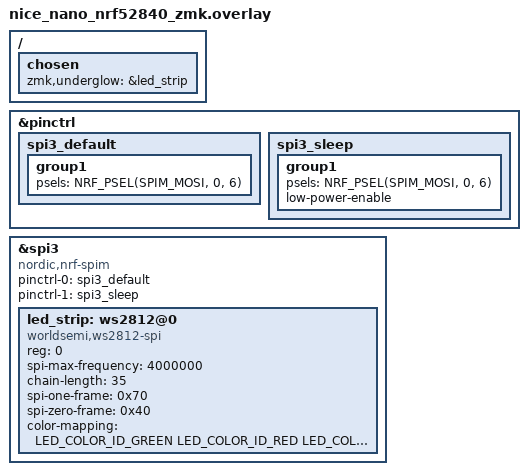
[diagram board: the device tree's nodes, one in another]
/*
 * Copyright (c) 2025 The ZMK Contributors
 * SPDX-License-Identifier: MIT
 * 
 * Aurora Sofle RGB for nice!nano v2
 * OLED is defined in shield-specific overlays
 */

#include <dt-bindings/led/led.h>

// Configure SPI pinctrl for RGB
&pinctrl {
    spi3_default: spi3_default {
        group1 {
            psels = <NRF_PSEL(SPIM_MOSI, 0, 6)>;
        };
    };

    spi3_sleep: spi3_sleep {
        group1 {
            psels = <NRF_PSEL(SPIM_MOSI, 0, 6)>;
            low-power-enable;
        };
    };
};

// Enable SPI for RGB LEDs
&spi3 {
    compatible = "nordic,nrf-spim";
    status = "okay";

    pinctrl-0 = <&spi3_default>;
    pinctrl-1 = <&spi3_sleep>;
    pinctrl-names = "default", "sleep";

    led_strip: ws2812@0 {
        compatible = "worldsemi,ws2812-spi";
        reg = <0>;
        spi-max-frequency = <4000000>;
        
        // Aurora Sofle: 35 LEDs per side (29 per-key + 6 underglow)
        chain-length = <35>;
        
        spi-one-frame = <0x70>;
        spi-zero-frame = <0x40>;
        color-mapping = <LED_COLOR_ID_GREEN LED_COLOR_ID_RED LED_COLOR_ID_BLUE>;
    };
};

/ {
    chosen {
        zmk,underglow = &led_strip;
    };
};
